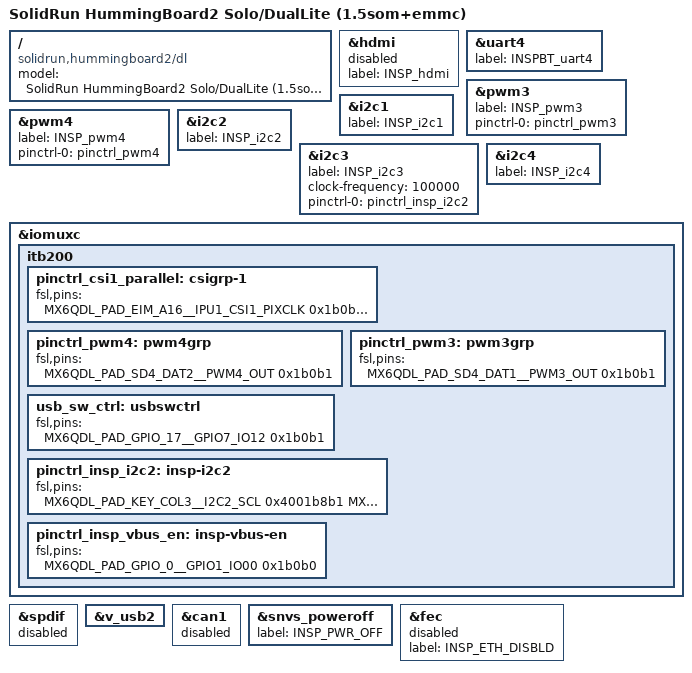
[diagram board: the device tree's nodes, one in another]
/*
 * Device Tree file for SolidRun HummingBoard2
 * Copyright (C) 2015 Rabeeh Khoury <rabeeh@solid-run.com>
 * Based on work by Russell King
 *
 * This file is dual-licensed: you can use it either under the terms
 * of the GPL or the X11 license, at your option. Note that this dual
 * licensing only applies to this file, and not this project as a
 * whole.
 *
 *  a) This file is free software; you can redistribute it and/or
 *     modify it under the terms of the GNU General Public License as
 *     published by the Free Software Foundation; either version 2 of the
 *     License.
 *
 *     This file is distributed in the hope that it will be useful
 *     but WITHOUT ANY WARRANTY; without even the implied warranty of
 *     MERCHANTABILITY or FITNESS FOR A PARTICULAR PURPOSE.  See the
 *     GNU General Public License for more details.
 *
 * Or, alternatively
 *
 *  b) Permission is hereby granted, free of charge, to any person
 *     obtaining a copy of this software and associated documentation
 *     files (the "Software"), to deal in the Software without
 *     restriction, including without limitation the rights to use
 *     copy, modify, merge, publish, distribute, sublicense, and/or
 *     sell copies of the Software, and to permit persons to whom the
 *     Software is furnished to do so, subject to the following
 *     conditions:
 *
 *     The above copyright notice and this permission notice shall be
 *     included in all copies or substantial portions of the Software.
 *
 *     THE SOFTWARE IS PROVIDED , WITHOUT WARRANTY OF ANY KIND
 *     EXPRESS OR IMPLIED, INCLUDING BUT NOT LIMITED TO THE WARRANTIES
 *     OF MERCHANTABILITY, FITNESS FOR A PARTICULAR PURPOSE AND
 *     NONINFRINGEMENT. IN NO EVENT SHALL THE AUTHORS OR COPYRIGHT
 *     HOLDERS BE LIABLE FOR ANY CLAIM, DAMAGES OR OTHER LIABILITY
 *     WHETHER IN AN ACTION OF CONTRACT, TORT OR OTHERWISE, ARISING
 *     FROM, OUT OF OR IN CONNECTION WITH THE SOFTWARE OR THE USE OR
 *     OTHER DEALINGS IN THE SOFTWARE.
 */
/dts-v1/;

#include "imx6dl.dtsi"
#include "imx6qdl-sr-som.dtsi"
#include "imx6qdl-sr-som-emmc.dtsi"
#include "imx6qdl-sr-som-brcm.dtsi"
#include "imx6qdl-hummingboard2.dtsi"

/ {
	model = "SolidRun HummingBoard2 Solo/DualLite (1.5som+emmc)";
	compatible = "solidrun,hummingboard2/dl", "fsl,imx6dl";
};

&hdmi {
    label = "INSP_hdmi";
    status = "disabled";
};

&uart4 {
    label = "INSPBT_uart4";
};

&pwm3 {
    label = "INSP_pwm3";
    pinctrl-names = "default";
    pinctrl-0 = <&pinctrl_pwm3>;
    status = "okay";
};

&pwm4 {
    label = "INSP_pwm4";
    #pwm-cells = <2>;
    pinctrl-names = "default";
    pinctrl-0 = <&pinctrl_pwm4>;
    status = "okay";
};

&i2c1 {
    label = "INSP_i2c1";
    status = "okay";
};

&i2c2 {
    label = "INSP_i2c2";
    status = "okay";
};

&i2c3 {
    label = "INSP_i2c3";
    status = "okay";
    clock-frequency = <100000>;
    pinctrl-names = "default";
    pinctrl-0 = <&pinctrl_insp_i2c2>;
};

&i2c4 {
    label = "INSP_i2c4";
    status = "okay";
};

&iomuxc {
    itb200 {
        pinctrl_csi1_parallel: csigrp-1 {
            fsl,pins = <
                /* DI1_DISP_CLK */
                MX6QDL_PAD_EIM_A16__IPU1_CSI1_PIXCLK    0x1b0b1
                /* DI1_PIN03 */
                MX6QDL_PAD_EIM_DA12__IPU1_CSI1_VSYNC    0x1b0b1
                /* DI1_PIN02 */
                MX6QDL_PAD_EIM_DA11__IPU1_CSI1_HSYNC    0x1b0b1
                /* CSI1_DATA12-19 */
                MX6QDL_PAD_EIM_A17__IPU1_CSI1_DATA12    0x1b0b1
                MX6QDL_PAD_EIM_A18__IPU1_CSI1_DATA13    0x1b0b1
                MX6QDL_PAD_EIM_A19__IPU1_CSI1_DATA14    0x1b0b1
                MX6QDL_PAD_EIM_A20__IPU1_CSI1_DATA15    0x1b0b1
                MX6QDL_PAD_EIM_A21__IPU1_CSI1_DATA16    0x1b0b1
                MX6QDL_PAD_EIM_A22__IPU1_CSI1_DATA17    0x1b0b1
                MX6QDL_PAD_EIM_A23__IPU1_CSI1_DATA18    0x1b0b1
                MX6QDL_PAD_EIM_A24__IPU1_CSI1_DATA19    0x1b0b1
            >;
        }; //~csigrp-1

        pinctrl_pwm4: pwm4grp {
            fsl,pins = <
                MX6QDL_PAD_SD4_DAT2__PWM4_OUT 0x1b0b1
            >;
        };

        pinctrl_pwm3: pwm3grp {
            fsl,pins = <
                MX6QDL_PAD_SD4_DAT1__PWM3_OUT 0x1b0b1
            >;
        };

        usb_sw_ctrl: usbswctrl {
            fsl,pins = <
                MX6QDL_PAD_GPIO_17__GPIO7_IO12 0x1b0b1
            >;
        };

        pinctrl_insp_i2c2: insp-i2c2 {
            fsl,pins = <
                MX6QDL_PAD_KEY_COL3__I2C2_SCL 0x4001b8b1
                MX6QDL_PAD_KEY_ROW3__I2C2_SDA 0x4001b8b1
            >;
        };

        pinctrl_insp_vbus_en: insp-vbus-en {
            fsl,pins = <MX6QDL_PAD_GPIO_0__GPIO1_IO00 0x1b0b0>;
        };

    }; //~itb200
}; //~iomuxc

&spdif {
    status = "disabled";
    /delete-property/ pinctrl-0;
};

&v_usb2 {
    /delete-property/ pinctrl-0;
};

&can1 {
    /delete-property/ pinctrl-0;
    status = "disabled";
};

&snvs_poweroff {
    label ="INSP_PWR_OFF";
    status = "okay";
};

&fec {
    status = "disabled";
    label = "INSP_ETH_DISBLD";
};

